# ATSAMRH71F20B register map
Vendor: Microchip Technology; Series: SAMRH71; File version: 0
CPU: CM7 r1p1, little endian, MPU, FPU, 3 interrupt priority bits
Registers are 32-bit, read-write, reset 0x0 unless marked. A register's access mark holds for its fields unless they carry their own. Offsets are from the block's base; [hi:lo] are bit positions; {n}, {i} and the like mark numbered series.

## SHA — Secure Hash Algorithm
Base 0x40094000; register names take the prefix SHA_
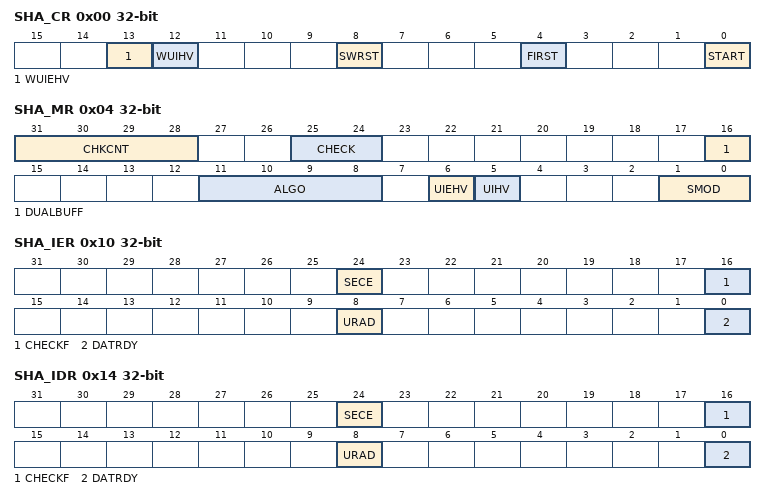
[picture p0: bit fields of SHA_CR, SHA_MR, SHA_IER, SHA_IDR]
0x00 SHA_CR wo — Control Register
  [13] WUIEHV — Write User Initial or Expected Hash Values
  [12] WUIHV — Write User Initial Hash Values
  [8] SWRST — Software Reset
  [4] FIRST — First Block of a Message
  [0] START — Start Processing
0x04 SHA_MR — Mode Register
  [31:28] CHKCNT — Check Counter
  [25:24] CHECK — Hash Check
    0=NO_CHECK (No check is performed); 1=CHECK_EHV (Check is performed with expected hash stored in internal expected hash value registers.); 2=CHECK_MESSAGE (Check is performed with expected hash provided after the message.)
  [16] DUALBUFF — Dual Input Buffer
    0=INACTIVE (SHA_IDATARx and SHA_IODATARx cannot be written during processing of previous block.); 1=ACTIVE (SHA_IDATARx and SHA_IODATARx can be written during processing of previous block when SMOD value = 2. It speeds up the overall runtime of large files.)
  [11:8] ALGO — SHA Algorithm
    0=SHA1 (SHA1 algorithm processed); 1=SHA256 (SHA256 algorithm processed); 2=SHA384 (SHA384 algorithm processed); 3=SHA512 (SHA512 algorithm processed); 4=SHA224 (SHA224 algorithm processed); 8=HMAC_SHA1 (HMAC algorithm with SHA1 Hash processed); 9=HMAC_SHA256 (HMAC algorithm with SHA256 Hash processed); 10=HMAC_SHA384 (HMAC algorithm with SHA384 Hash processed); 11=HMAC_SHA512 (HMAC algorithm with SHA512 Hash processed); 12=HMAC_SHA224 (HMAC algorithm with SHA224 Hash processed)
  [6] UIEHV — User Initial or Expected Hash Value Registers
  [5] UIHV — User Initial Hash Value Registers
  [1:0] SMOD — Start Mode
    0=MANUAL_START (Manual mode); 1=AUTO_START (Auto mode); 2=IDATAR0_START (SHA_IDATAR0 access only mode (mandatory when DMA is used))
0x10 SHA_IER wo — Interrupt Enable Register
  [24] SECE — Safety Event Interrupt Enable
  [16] CHECKF — Check Done Interrupt Enable
  [8] URAD — Unspecified Register Access Detection Interrupt Enable
  [0] DATRDY — Data Ready Interrupt Enable
0x14 SHA_IDR wo — Interrupt Disable Register
  [24] SECE — Safety Event Interrupt Disable
  [16] CHECKF — Check Done Interrupt Disable
  [8] URAD — Unspecified Register Access Detection Interrupt Disable
  [0] DATRDY — Data Ready Interrupt Disable
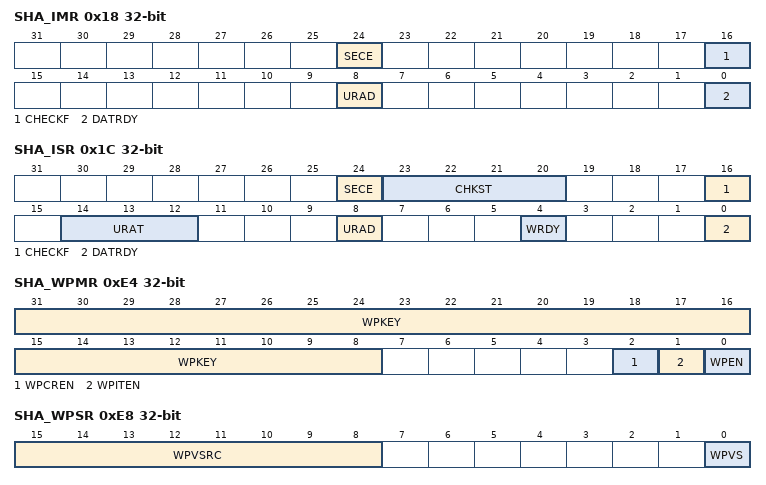
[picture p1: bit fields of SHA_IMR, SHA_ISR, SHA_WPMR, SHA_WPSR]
0x18 SHA_IMR ro — Interrupt Mask Register
  [24] SECE — Safety Event Interrupt Mask
  [16] CHECKF — Check Done Interrupt Mask
  [8] URAD — Unspecified Register Access Detection Interrupt Mask
  [0] DATRDY — Data Ready Interrupt Mask
0x1C SHA_ISR ro — Interrupt Status Register
  [24] SECE — Security and/or Safety Event
  [23:20] CHKST — Check Status (cleared by writing START or SWRST bits in SHA_CR or by reading SHA_IODATARx)
  [16] CHECKF — Check Done Status (cleared by writing START or SWRST bits in SHA_CR or by reading SHA_IODATARx)
  [14:12] URAT — Unspecified Register Access Type (cleared by writing a 1 to SWRST bit in SHA_CR)
  [8] URAD — Unspecified Register Access Detection Status (cleared by writing a 1 to SWRST bit in SHA_CR)
  [4] WRDY — Input Data Register Write Ready
  [0] DATRDY — Data Ready (cleared by writing a 1 to bit SWRST or START in SHA_CR, or by reading SHA_IODATARx)
0x20 SHA_MSR — Message Size Register
  [31:0] MSGSIZE — Message Size
0x30 SHA_BCR — Bytes Count Register
  [31:0] BYTCNT — Remaining Byte Count Before Auto Padding
{0x40+4i} SHA_IDATAR{i} wo (i=0..15) — Input Data 0 Register {i}
  [31:0] IDATA — Input Data
{0x80+4i} SHA_IODATAR{i} (i=0..15) — Input/Output Data 0 Register {i}
  [31:0] IODATA — Input/Output Data
0xE4 SHA_WPMR — Write Protection Mode Register
  [31:8] WPKEY — Write Protection Key
    0x534841=PASSWD (Writing any other value in this field aborts the write operation of the WPEN,WPITEN,WPCREN bits.Always reads as 0.)
  [2] WPCREN — Write Protection Control Enable
  [1] WPITEN — Write Protection Interruption Enable
  [0] WPEN — Write Protection Configuration Enable
0xE8 SHA_WPSR ro — Write Protection Status Register
  [15:8] WPVSRC — Write Protection Violation Source
  [0] WPVS — Write Protection Violation Status (cleared on read)
